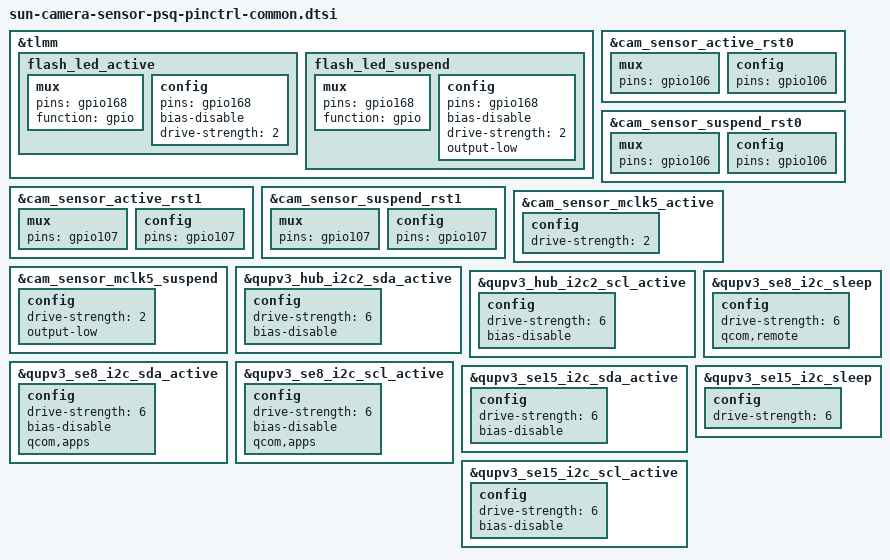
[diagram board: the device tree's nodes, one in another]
&tlmm {
	flash_led_active: flash_led_active {
		mux {
			pins = "gpio168";
			function = "gpio";
		};

		config {
			pins = "gpio168";
			bias-disable;
			drive-strength = <2>;
		};
	};

	flash_led_suspend: flash_led_suspend {
		mux {
			pins = "gpio168";
			function = "gpio";
		};

		config {
			pins = "gpio168";
			bias-disable;
			drive-strength = <2>;
			output-low;
		};
	};
};

&cam_sensor_active_rst0 {
	mux {
		pins = "gpio106";
	};

	config {
		pins = "gpio106";
	};
};

&cam_sensor_suspend_rst0 {
	mux {
		pins = "gpio106";
	};

	config {
		pins = "gpio106";
	};
};

&cam_sensor_active_rst1 {
	mux {
		pins = "gpio107";
	};

	config {
		pins = "gpio107";
	};
};

&cam_sensor_suspend_rst1 {
	mux {
		pins = "gpio107";
	};

	config {
		pins = "gpio107";
	};
};

&cam_sensor_mclk5_active {
	config {
		drive-strength = <2>;
	};
};

&cam_sensor_mclk5_suspend {
	config {
		drive-strength = <2>;
		output-low;
	};
};

&qupv3_hub_i2c2_sda_active {
	config {
		drive-strength = <6>;
		bias-disable;
	};
};

&qupv3_hub_i2c2_scl_active {
	config {
		drive-strength = <6>;
		bias-disable;
	};
};

&qupv3_se8_i2c_sda_active {
	config {
		drive-strength = <6>;
		bias-disable;
		qcom,apps;
	};
};

&qupv3_se8_i2c_scl_active {
	config {
		drive-strength = <6>;
		bias-disable;
		qcom,apps;
	};
};

&qupv3_se8_i2c_sleep {
	config {
		drive-strength = <6>;
		qcom,remote;
	};
};

&qupv3_se15_i2c_sda_active {
	config {
		drive-strength = <6>;
		bias-disable;
	};
};

&qupv3_se15_i2c_scl_active {
	config {
		drive-strength = <6>;
		bias-disable;
	};
};

&qupv3_se15_i2c_sleep {
	config {
		drive-strength = <6>;
	};
};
